# STM32G563xx register map
File version: 1.0
Registers are 32-bit, read-write, reset 0x0 unless marked. A register's access mark holds for its fields unless they carry their own. Offsets are from the block's base; [hi:lo] are bit positions; {n}, {i} and the like mark numbered series.

## OPAMP1 — Operational amplifier (OPAMP)
Base 0x44005C00
Same registers: OPAMP2 0x44006000, OPAMP3 0x44006400
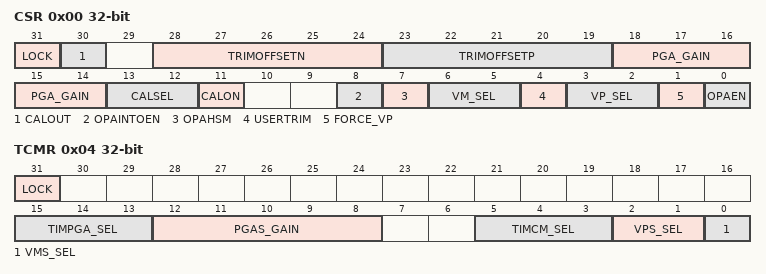
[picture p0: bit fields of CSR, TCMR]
0x00 CSR — OPAMP control/status register
  [31] LOCK — OPAMP_CSR register lock
  [30] CALOUT
  [28:24] TRIMOFFSETN — Trim for NMOS differential pairs
  [23:19] TRIMOFFSETP — Trim for PMOS differential pairs
  [18:14] PGA_GAIN
  [13:12] CALSEL — Calibration selection
  [11] CALON — Calibration mode enable
  [8] OPAINTOEN
  [7] OPAHSM — Operational amplifier high-speed mode
  [6:5] VM_SEL — Inverting input primary selection
  [4] USERTRIM — User trimming enable
  [3:2] VP_SEL — Noninverting input primary selection
  [1] FORCE_VP
  [0] OPAEN — Operational amplifier enable
0x04 TCMR — OPAMP timer-controlled mode register
  [31] LOCK — OPAMP_TCMR register lock
  [15:13] TIMPGA_SEL
  [12:8] PGAS_GAIN
  [5:3] TIMCM_SEL
  [2:1] VPS_SEL
  [0] VMS_SEL

## VREFBUF — Voltage reference buffer (VREFBUF)
Base 0x44007400
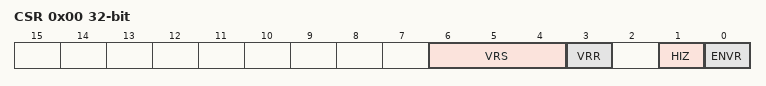
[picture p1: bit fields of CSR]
0x00 CSR — VREFBUF control and status register
  [6:4] VRS — Voltage reference scale
  [3] VRR — Voltage reference buffer ready
  [1] HIZ — High impedance mode
  [0] ENVR — Voltage reference buffer mode enable
0x04 CCR — VREFBUF calibration control register
  [5:0] TRIM — Trimming code

## TAMP — Tamper and backup registers (TAMP)
Base 0x44007C00
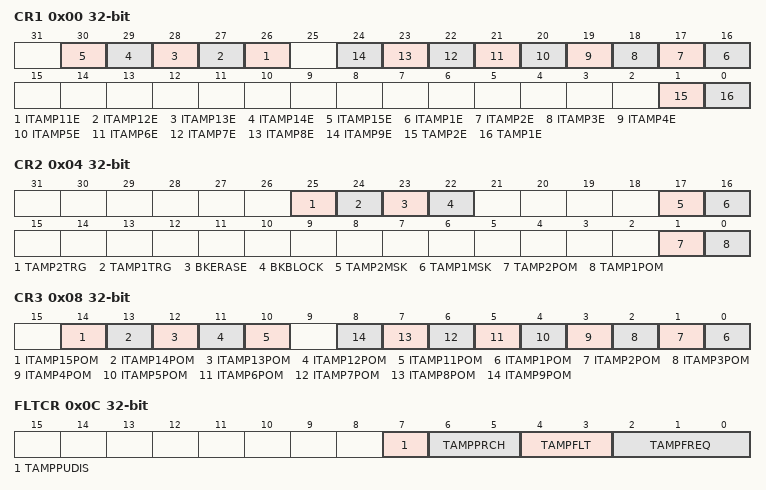
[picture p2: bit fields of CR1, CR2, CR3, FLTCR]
0x00 CR1 — TAMP control register 1
  [n+15] ITAMP{n}E (n=11..15) — Internal tamper {n} enable
  [n+15] ITAMP{n}E (n=1..9) — Internal tamper {n} enable
  [1] TAMP2E — Tamper detection on TAMP_IN2 enable
  [0] TAMP1E — Tamper detection on TAMP_IN1 enable
0x04 CR2 — TAMP control register 2
  [25] TAMP2TRG — Active level for tamper 2 input
  [24] TAMP1TRG — Active level for tamper 1 input
  [23] BKERASE
  [22] BKBLOCK
  [17] TAMP2MSK — Tamper 2 mask
  [16] TAMP1MSK — Tamper 1 mask
  [1] TAMP2POM — Tamper 2 potential mode
  [0] TAMP1POM — Tamper 1 potential mode
0x08 CR3 — TAMP control register 3
  [14] ITAMP15POM — Internal tamper 15 potential mode
  [13] ITAMP14POM — Internal Tamper 14 potential mode
  [12] ITAMP13POM — Internal tamper 13 potential mode
  [11] ITAMP12POM — Internal tamper 12 potential mode
  [10] ITAMP11POM — Internal tamper 11 potential mode
  [n-1] ITAMP{n}POM (n=1..9) — Internal tamper {n} potential mode
0x0C FLTCR — TAMP filter control register
  [7] TAMPPUDIS — TAMP_INx pull-up disable
  [6:5] TAMPPRCH — TAMP_INx precharge duration
  [4:3] TAMPFLT — TAMP_INx filter count
  [2:0] TAMPFREQ — Tamper sampling frequency
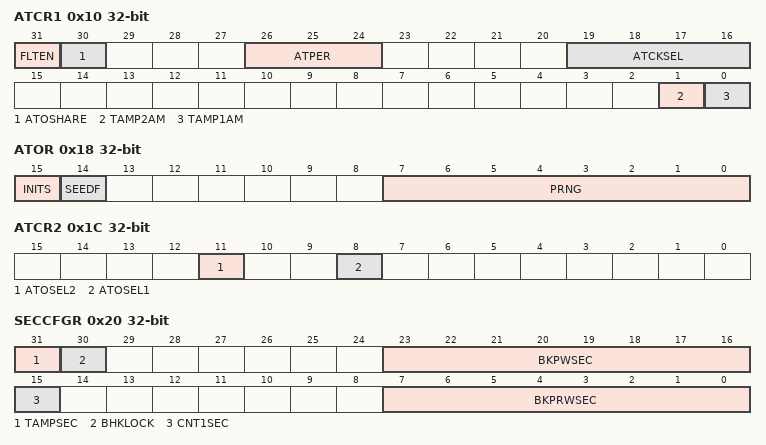
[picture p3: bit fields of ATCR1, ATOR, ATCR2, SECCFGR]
0x10 ATCR1 — TAMP active tamper control register 1
  [31] FLTEN — Active tamper filter enable
  [30] ATOSHARE — Active tamper output sharing
  [26:24] ATPER — Active tamper output change period
  [19:16] ATCKSEL
  [1] TAMP2AM — Tamper 2 active mode
  [0] TAMP1AM — Tamper 1 active mode
0x14 ATSEEDR — TAMP active tamper seed register
  [31:0] SEED — Pseudo-random generator seed value
0x18 ATOR ro — TAMP active tamper output register
  [15] INITS — Active tamper initialization status
  [14] SEEDF — Seed running flag
  [7:0] PRNG — Pseudo-random generator value
0x1C ATCR2 — TAMP active tamper control register 2
  [11] ATOSEL2, [8] ATOSEL1
0x20 SECCFGR — TAMP secure configuration register
  [31] TAMPSEC
  [30] BHKLOCK — Boot hardware key lock
  [23:16] BKPWSEC
  [15] CNT1SEC
  [7:0] BKPRWSEC
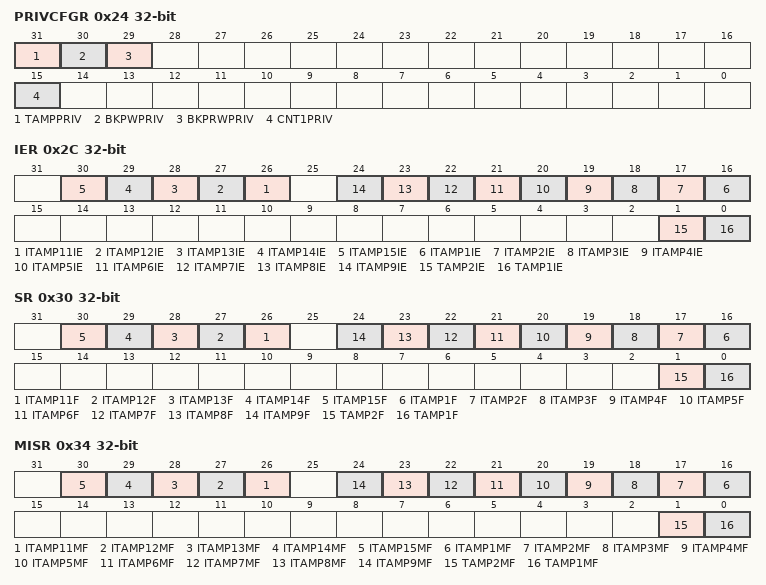
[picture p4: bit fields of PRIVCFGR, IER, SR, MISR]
0x24 PRIVCFGR — TAMP privilege configuration register
  [31] TAMPPRIV, [30] BKPWPRIV, [29] BKPRWPRIV, [15] CNT1PRIV
0x2C IER — TAMP interrupt enable register
  [n+15] ITAMP{n}IE (n=11..15) — Internal tamper {n} interrupt enable
  [n+15] ITAMP{n}IE (n=1..9) — Internal tamper {n} interrupt enable
  [1] TAMP2IE — Tamper 2 interrupt enable
  [0] TAMP1IE — Tamper 1 interrupt enable
0x30 SR ro — TAMP status register
  [n+15] ITAMP{n}F (n=11..15) — Internal tamper {n} flag
  [n+15] ITAMP{n}F (n=1..9) — Internal tamper {n} flag
  [1] TAMP2F — TAMP2 detection flag
  [0] TAMP1F — TAMP1 detection flag
0x34 MISR ro — TAMP nonsecure masked interrupt status register
  [n+15] ITAMP{n}MF (n=11..15), [n+15] ITAMP{n}MF (n=1..9), [1] TAMP2MF, [0] TAMP1MF
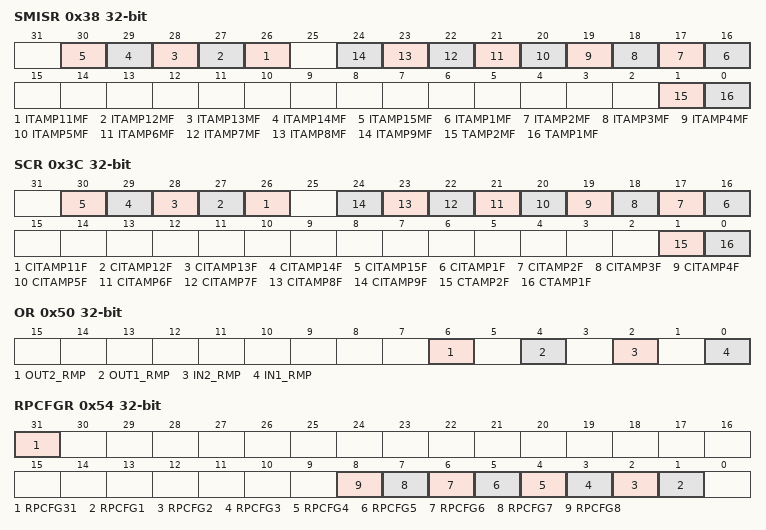
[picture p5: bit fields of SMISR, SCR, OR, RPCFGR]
0x38 SMISR ro — TAMP secure masked interrupt status register
  [n+15] ITAMP{n}MF (n=11..15)
  [n+15] ITAMP{n}MF (n=1..9)
  [1] TAMP2MF — TAMP2 secure interrupt masked flag
  [0] TAMP1MF — TAMP1 secure interrupt masked flag
0x3C SCR — TAMP status clear register
  [n+15] CITAMP{n}F (n=11..15) — Clear ITAMP{n} detection flag
  [n+15] CITAMP{n}F (n=1..9) — Clear ITAMP{n} detection flag
  [1] CTAMP2F — Clear TAMP2 detection flag
  [0] CTAMP1F — Clear TAMP1 detection flag
0x40 COUNT1R — TAMP monotonic counter 1 register
  [31:0] COUNT
0x50 OR — TAMP option register
  [6] OUT2_RMP — TAMP_OUT2 mapping
  [4] OUT1_RMP — TAMP_OUT1 mapping
  [2] IN2_RMP — TAMP_IN2 mapping
  [0] IN1_RMP — TAMP_IN1 mapping
0x54 RPCFGR — TAMP resources protection configuration register
  [31] RPCFG31 — Backup registers protection
  [n] RPCFG{n} (n=1..8) — Configurable resource {n} protection
{0x100+4i} BKP{i}R (i=0..31) — TAMP backup {i} register
  [31:0] BKP
